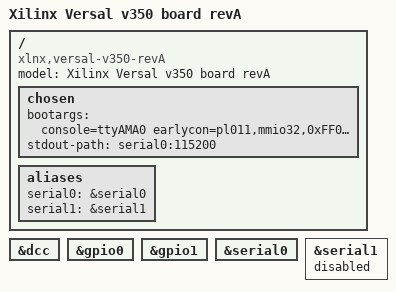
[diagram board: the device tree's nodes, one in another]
// SPDX-License-Identifier: GPL-2.0
/*
 * dts file for Xilinx Versal v350 revA
 *
 * (C) Copyright 2019-2022 Xilinx, Inc.
 * (C) Copyright 2022 Advanced Micro Devices, Inc. All Rights Reserved.
 *
 * Michal Simek <michal.simek@xilinx.com>
 */


/ {
	compatible = "xlnx,versal-v350-revA", "xlnx,versal";
	model = "Xilinx Versal v350 board revA";

	chosen {
		bootargs = "console=ttyAMA0 earlycon=pl011,mmio32,0xFF010000,115200n8 clk_ignore_unused";
		stdout-path = "serial0:115200";
	};

	aliases {
		serial0 = &serial0;
		serial1 = &serial1;
	};
};

&dcc {
	status = "okay";
};

&gpio0 {
	status = "okay";
};

&gpio1 {
	status = "okay";
};

&serial0 {
	status = "okay";
};

&serial1 {
	status = "disabled"; /* communication with MSP432 */
};
